AUTOSAR XML (schema 314)
package /ComponentType
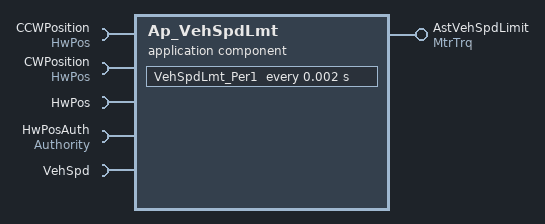
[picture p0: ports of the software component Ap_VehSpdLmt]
  application software component type Ap_VehSpdLmt
    provide port AstVehSpdLimit: unqueued-sender-com-spec{data-element=MtrNm_f32, can-invalidate=false, init-value=D_MTRTRQCMDHILMT_MTRNM_F32}, provided-interface=MtrTrq
    5 x require port:
      CCWPosition: unqueued-receiver-com-spec{data-element=HwDeg_f32, init-value=D_ZERO_ULS_F32}, required-interface=HwPos
      CWPosition: unqueued-receiver-com-spec{data-element=HwDeg_f32, init-value=D_ZERO_ULS_F32}, required-interface=HwPos
      HwPos: unqueued-receiver-com-spec{data-element=HwDeg_f32, init-value=D_ZERO_ULS_F32}, required-interface=HwPos
      HwPosAuth: unqueued-receiver-com-spec{data-element=Uls_f32, init-value=D_ZERO_ULS_F32}, required-interface=Authority
      VehSpd: unqueued-receiver-com-spec{data-element=Kph_f32, init-value=D_ZERO_ULS_F32}, required-interface=VehSpd
  internal behavior Ap_VehSpdLmt_InternalBehavior: component=Ap_VehSpdLmt
    timing event TMT_VehSpdLmt_Per1: start-on-event=VehSpdLmt_Per1, period=0.002
    port-api-options:
      enable-take-address=false, indirect-api=false, port=AstVehSpdLimit
      enable-take-address=false, indirect-api=false, port=CCWPosition
      enable-take-address=false, indirect-api=false, port=CWPosition
      enable-take-address=false, indirect-api=false, port=HwPos
      enable-take-address=false, indirect-api=false, port=HwPosAuth
      enable-take-address=false, indirect-api=false, port=VehSpd
    runnable VehSpdLmt_Per1
      5 x data read access:
        READ_CCWPosition_HwDeg_f32: data-element=CCWPosition.HwDeg_f32
        READ_CWPosition_HwDeg_f32: data-element=CWPosition.HwDeg_f32
        READ_HwPos_HwDeg_f32: data-element=HwPos.HwDeg_f32
        READ_HwPosAuth_Uls_f32: data-element=HwPosAuth.Uls_f32
        READ_VehSpd_Kph_f32: data-element=VehSpd.Kph_f32
      data write access WRITE_AstVehSpdLimit_MtrNm_f32: data-element=AstVehSpdLimit.MtrNm_f32
  swc implementation Ap_VehSpdLmt_Implementation: behavior=Ap_VehSpdLmt_InternalBehavior
    code-descriptors:
      code Code: type=SRC
